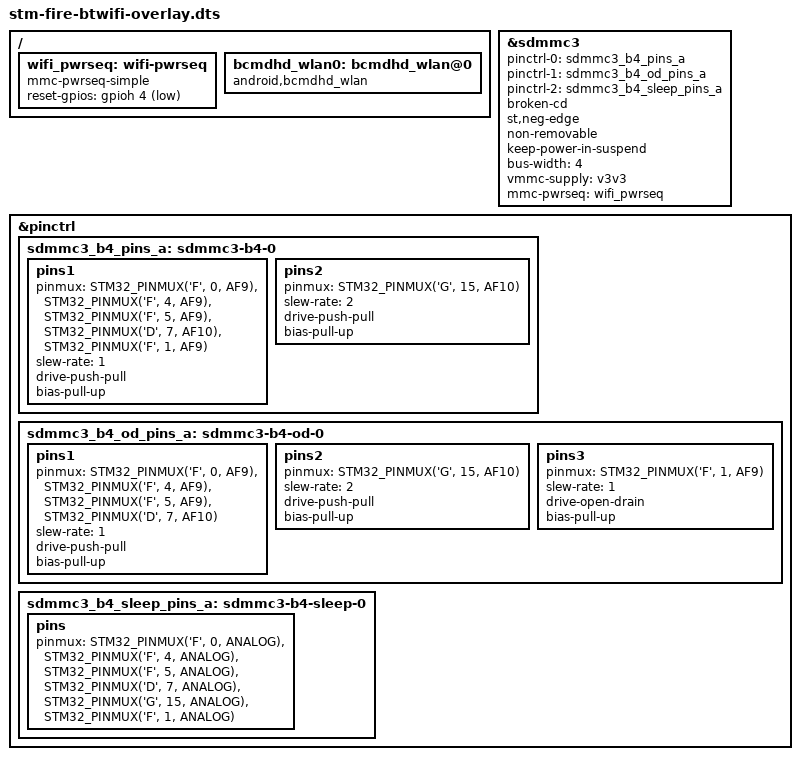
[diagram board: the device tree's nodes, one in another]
// SPDX-License-Identifier: (GPL-2.0+ OR BSD-3-Clause)
/*
 * Copyright (C) STMicroelectronics 2018 - All Rights Reserved
 * Author: Alexandre Torgue <alexandre.torgue@st.com>.
 */

/dts-v1/;
/plugin/;
//#include "../stm32mp157c.dtsi"
#include <dt-bindings/pinctrl/stm32-pinfunc.h>
#include <dt-bindings/input/input.h>
#include <dt-bindings/mfd/st,stpmic1.h>
#include <dt-bindings/gpio/gpio.h>

/{
	fragment@0{
		target=<&sdmmc3>;
		__overlay__{
			pinctrl-names = "default", "opendrain", "sleep";
			pinctrl-0 = <&sdmmc3_b4_pins_a>;
			pinctrl-1 = <&sdmmc3_b4_od_pins_a>;
			pinctrl-2 = <&sdmmc3_b4_sleep_pins_a>;
			broken-cd;
			st,neg-edge;
			non-removable;
			keep-power-in-suspend;
			bus-width = <4>;
			vmmc-supply = <&v3v3>;
			mmc-pwrseq = <&wifi_pwrseq>;	
			status = "okay";
		};
	};

	fragment@1{
		target=<&pinctrl>;
		__overlay__{
			sdmmc3_b4_pins_a: sdmmc3-b4-0 {
				pins1 {
					pinmux = <STM32_PINMUX('F', 0, AF9)>, /* SDMMC3_D0 */
						 <STM32_PINMUX('F', 4, AF9)>, /* SDMMC3_D1 */
						 <STM32_PINMUX('F', 5, AF9)>, /* SDMMC3_D2 */
						 <STM32_PINMUX('D', 7, AF10)>, /* SDMMC3_D3 */
						 <STM32_PINMUX('F', 1, AF9)>; /* SDMMC3_CMD */
					slew-rate = <1>;
					drive-push-pull;
					bias-pull-up;
				};
				pins2 {
					pinmux = <STM32_PINMUX('G', 15, AF10)>; /* SDMMC3_CK */
					slew-rate = <2>;
					drive-push-pull;
					bias-pull-up;
				};
			};

			sdmmc3_b4_od_pins_a: sdmmc3-b4-od-0 {
				pins1 {
					pinmux = <STM32_PINMUX('F', 0, AF9)>, /* SDMMC3_D0 */
						 <STM32_PINMUX('F', 4, AF9)>, /* SDMMC3_D1 */
						 <STM32_PINMUX('F', 5, AF9)>, /* SDMMC3_D2 */
						 <STM32_PINMUX('D', 7, AF10)>; /* SDMMC3_D3 */
					slew-rate = <1>;
					drive-push-pull;
					bias-pull-up;
				};
				pins2 {
					pinmux = <STM32_PINMUX('G', 15, AF10)>; /* SDMMC3_CK */
					slew-rate = <2>;
					drive-push-pull;
					bias-pull-up;
				};
				pins3 {
					pinmux = <STM32_PINMUX('F', 1, AF9)>; /* SDMMC3_CMD */
					slew-rate = <1>;
					drive-open-drain;
					bias-pull-up;
				};
			};

			sdmmc3_b4_sleep_pins_a: sdmmc3-b4-sleep-0 {
				pins {
					pinmux = <STM32_PINMUX('F', 0, ANALOG)>, /* SDMMC3_D0 */
						 <STM32_PINMUX('F', 4, ANALOG)>, /* SDMMC3_D1 */
						 <STM32_PINMUX('F', 5, ANALOG)>, /* SDMMC3_D2 */
						 <STM32_PINMUX('D', 7, ANALOG)>, /* SDMMC3_D3 */
						 <STM32_PINMUX('G', 15, ANALOG)>, /* SDMMC3_CK */
						 <STM32_PINMUX('F', 1, ANALOG)>; /* SDMMC3_CMD */
				};
			};

		};
	};

	fragment@2{
		target-path="/";
		__overlay__{
			wifi_pwrseq: wifi-pwrseq {
				compatible = "mmc-pwrseq-simple";
				reset-gpios = <&gpioh 4 GPIO_ACTIVE_LOW>;
			};

			bcmdhd_wlan0: bcmdhd_wlan@0 {
				compatible = "android,bcmdhd_wlan";
				status = "okay";
			};			
		};
	};
};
